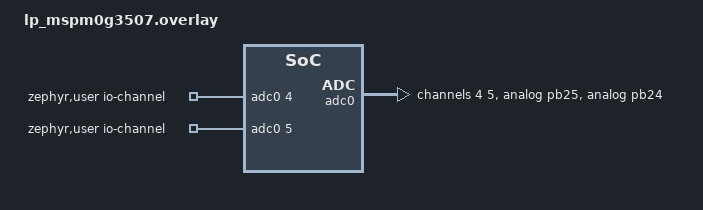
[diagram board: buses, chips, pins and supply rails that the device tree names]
/*
 * Copyright (c) 2026 Linumiz
 *
 * SPDX-License-Identifier: Apache-2.0
 */

#include <dt-bindings/adc/adc.h>

/ {
	zephyr,user {
		io-channels = <&adc0 4>, <&adc0 5>;
	};
};

&adc0 {
	clocks = <&ckm MSPM0_CLOCK_ULPCLK>;
	ti,clk-divider = <1>;
	ti,clk-range = <6>;
	max-result-reg = <12>;
	pinctrl-0 = <&analog_pb25 &analog_pb24>;
	pinctrl-names = "default";
	status = "okay";
	#address-cells = <1>;
	#size-cells = <0>;

	channel@4 {
		reg = <4>;
		zephyr,gain = "ADC_GAIN_1";
		zephyr,reference = "ADC_REF_VDD_1";
		zephyr,acquisition-time = <ADC_ACQ_TIME_DEFAULT>;
		zephyr,resolution = <12>;
	};

	channel@5 {
		reg = <5>;
		zephyr,gain = "ADC_GAIN_1";
		zephyr,reference = "ADC_REF_VDD_1";
		zephyr,acquisition-time = <ADC_ACQ_TIME_DEFAULT>;
		zephyr,resolution = <12>;
	};
};
